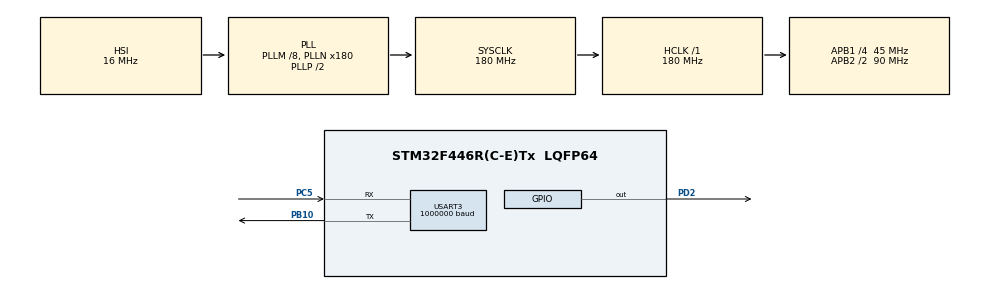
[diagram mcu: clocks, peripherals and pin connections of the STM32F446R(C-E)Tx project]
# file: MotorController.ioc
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Dma.Request0=USART3_RX
Dma.USART3_RX.0.Direction=DMA_PERIPH_TO_MEMORY
Dma.USART3_RX.0.FIFOMode=DMA_FIFOMODE_DISABLE
Dma.USART3_RX.0.Instance=DMA1_Stream1
Dma.USART3_RX.0.MemDataAlignment=DMA_MDATAALIGN_BYTE
Dma.USART3_RX.0.MemInc=DMA_MINC_ENABLE
Dma.USART3_RX.0.Mode=DMA_CIRCULAR
Dma.USART3_RX.0.PeriphDataAlignment=DMA_PDATAALIGN_BYTE
Dma.USART3_RX.0.PeriphInc=DMA_PINC_DISABLE
Dma.USART3_RX.0.Priority=DMA_PRIORITY_LOW
Mcu.Family=STM32F4
Mcu.Name=STM32F446R(C-E)Tx
Mcu.Package=LQFP64
NVIC.DMA1_Stream1_IRQn=true\:0\:0\:false\:false\:true\:false\:true
NVIC.PriorityGroup=NVIC_PRIORITYGROUP_4
NVIC.USART3_IRQn=true\:0\:0\:false\:false\:true\:true\:true
PA13.Mode=Serial_Wire
PA13.Signal=SYS_JTMS-SWDIO
PA14.Mode=Serial_Wire
PA14.Signal=SYS_JTCK-SWCLK
PB10.Mode=Asynchronous
PB10.Signal=USART3_TX
PC5.Mode=Asynchronous
PC5.Signal=USART3_RX
PD2.Signal=GPIO_Output
PH0-OSC_IN.Mode=HSE-External-Oscillator
PH0-OSC_IN.Signal=RCC_OSC_IN
PH1-OSC_OUT.Mode=HSE-External-Oscillator
PH1-OSC_OUT.Signal=RCC_OSC_OUT
ProjectManager.HeapSize=0x200
ProjectManager.StackSize=0x400
ProjectManager.TargetToolchain=STM32CubeIDE
RCC.AHBFreq_Value=180000000
RCC.APB1CLKDivider=RCC_HCLK_DIV4
RCC.APB1Freq_Value=45000000
RCC.APB1TimFreq_Value=90000000
RCC.APB2CLKDivider=RCC_HCLK_DIV2
RCC.APB2Freq_Value=90000000
RCC.APB2TimFreq_Value=180000000
RCC.CortexFreq_Value=180000000
RCC.HCLKFreq_Value=180000000
RCC.HSE_VALUE=25000000
RCC.PLLM=8
RCC.PLLN=180
RCC.SYSCLKFreq_VALUE=180000000
RCC.SYSCLKSource=RCC_SYSCLKSOURCE_PLLCLK
RCC.USBFreq_Value=180000000
RCC.VCOOutputFreq_Value=360000000
USART3.BaudRate=1000000
USART3.Mode=MODE_TX_RX
USART3.VirtualMode=VM_ASYNC
board=custom

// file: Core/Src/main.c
/* USER CODE BEGIN Header */
/**
  ******************************************************************************
  * @file           : main.c
  * @brief          : Main program body
  ******************************************************************************
  * @attention
  *
  * <h2><center>&copy; Copyright (c) 2021 STMicroelectronics.
  * All rights reserved.</center></h2>
  *
  * This software component is licensed by ST under BSD 3-Clause license,
  * the "License"; You may not use this file except in compliance with the
  * License. You may obtain a copy of the License at:
  *                        opensource.org/licenses/BSD-3-Clause
  *
  ******************************************************************************
  */
/* USER CODE END Header */
#include "main.h"
#include "dma.h"
#include "usart.h"
#include "gpio.h"

/* USER CODE BEGIN Includes */
#include "../../ScueDK/scuedk_embedded/slave/inc/serial_line.h"
#include "../../ScueDK/structs/structs.h"
/* USER CODE END Includes */

/* USER CODE BEGIN PD */
#define RX_BUFFER_SIZE 300
/* USER CODE END PD */

/* USER CODE BEGIN PV */
uint8_t rxBuffer[RX_BUFFER_SIZE];
SerialLine serialLine;
FlipperController fc;
TrackController tc;
int cnt = 0;
int plen;
/* USER CODE END PV */

void SystemClock_Config(void);

int main(void)
{

  /* MCU Configuration--------------------------------------------------------*/

  /* Reset of all peripherals, Initializes the Flash interface and the Systick. */
  HAL_Init();

  /* USER CODE BEGIN Init */
  //initSerialLine(&serialLine, 1, (uint8_t*)&fc, sizeof(fc), USART3);
  initSerialLine(&serialLine, 2, (uint8_t*)&tc, sizeof(tc), USART3);
  /* USER CODE END Init */

  /* Configure the system clock */
  SystemClock_Config();

  /* Initialize all configured peripherals */
  MX_GPIO_Init();
  MX_DMA_Init();
  MX_USART3_UART_Init();
  /* USER CODE BEGIN 2 */
  LL_DMA_SetMemoryAddress(DMA1, LL_DMA_STREAM_1, (uint32_t)rxBuffer);
  LL_DMA_SetPeriphAddress(DMA1, LL_DMA_STREAM_1, (uint32_t)&USART3->DR);
  LL_DMA_SetDataLength(DMA1, LL_DMA_STREAM_1, RX_BUFFER_SIZE);
  LL_DMA_EnableStream(DMA1, LL_DMA_STREAM_1);
  LL_USART_EnableDMAReq_RX(USART3);
  LL_USART_EnableIT_IDLE(USART3);
  /* USER CODE END 2 */

  /* Infinite loop */
  while (1)
  {

    /* USER CODE BEGIN 3 */
	  cnt++;
  }
  /* USER CODE END 3 */
}

void SystemClock_Config(void)
{
  RCC_OscInitTypeDef RCC_OscInitStruct = {0};
  RCC_ClkInitTypeDef RCC_ClkInitStruct = {0};

  /** Configure the main internal regulator output voltage
  */
  __HAL_RCC_PWR_CLK_ENABLE();
  __HAL_PWR_VOLTAGESCALING_CONFIG(PWR_REGULATOR_VOLTAGE_SCALE1);
  /** Initializes the RCC Oscillators according to the specified parameters
  * in the RCC_OscInitTypeDef structure.
  */
  RCC_OscInitStruct.OscillatorType = RCC_OSCILLATORTYPE_HSI;
  RCC_OscInitStruct.HSIState = RCC_HSI_ON;
  RCC_OscInitStruct.HSICalibrationValue = RCC_HSICALIBRATION_DEFAULT;
  RCC_OscInitStruct.PLL.PLLState = RCC_PLL_ON;
  RCC_OscInitStruct.PLL.PLLSource = RCC_PLLSOURCE_HSI;
  RCC_OscInitStruct.PLL.PLLM = 8;
  RCC_OscInitStruct.PLL.PLLN = 180;
  RCC_OscInitStruct.PLL.PLLP = RCC_PLLP_DIV2;
  RCC_OscInitStruct.PLL.PLLQ = 2;
  RCC_OscInitStruct.PLL.PLLR = 2;
  if (HAL_RCC_OscConfig(&RCC_OscInitStruct) != HAL_OK)
  {
    Error_Handler();
  }
  /** Activate the Over-Drive mode
  */
  if (HAL_PWREx_EnableOverDrive() != HAL_OK)
  {
    Error_Handler();
  }
  /** Initializes the CPU, AHB and APB buses clocks
  */
  RCC_ClkInitStruct.ClockType = RCC_CLOCKTYPE_HCLK|RCC_CLOCKTYPE_SYSCLK
                              |RCC_CLOCKTYPE_PCLK1|RCC_CLOCKTYPE_PCLK2;
  RCC_ClkInitStruct.SYSCLKSource = RCC_SYSCLKSOURCE_PLLCLK;
  RCC_ClkInitStruct.AHBCLKDivider = RCC_SYSCLK_DIV1;
  RCC_ClkInitStruct.APB1CLKDivider = RCC_HCLK_DIV4;
  RCC_ClkInitStruct.APB2CLKDivider = RCC_HCLK_DIV2;

  if (HAL_RCC_ClockConfig(&RCC_ClkInitStruct, FLASH_LATENCY_5) != HAL_OK)
  {
    Error_Handler();
  }
}

void Error_Handler(void)
{
  __disable_irq();
  while (1)
  {
  }
}

/************************ (C) COPYRIGHT STMicroelectronics *****END OF FILE****/
